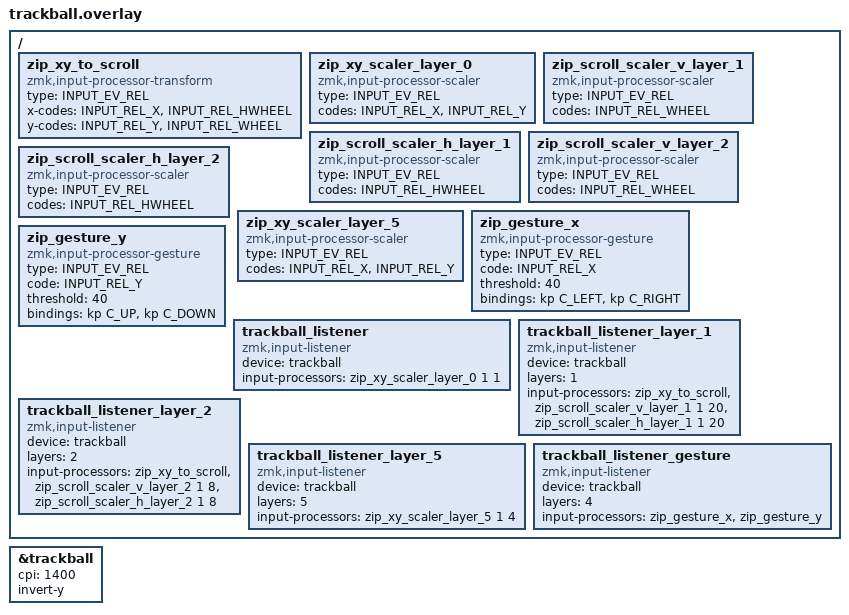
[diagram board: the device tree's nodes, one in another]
// Trackball overlay - generated by Skinner39 Studio

/ {
    // XY入力をスクロールイベントに変換する共有プロセッサ
    zip_xy_to_scroll: zip_xy_to_scroll {
        compatible = "zmk,input-processor-transform";
        #input-processor-cells = <0>;
        type = <INPUT_EV_REL>;
        x-codes = <INPUT_REL_X>, <INPUT_REL_HWHEEL>;
        y-codes = <INPUT_REL_Y>, <INPUT_REL_WHEEL>;
    };

    zip_xy_scaler_layer_0: zip_xy_scaler_layer_0 {
        compatible = "zmk,input-processor-scaler";
        #input-processor-cells = <2>;
        type = <INPUT_EV_REL>;
        codes = <INPUT_REL_X>, <INPUT_REL_Y>;
    };

    zip_scroll_scaler_v_layer_1: zip_scroll_scaler_v_layer_1 {
        compatible = "zmk,input-processor-scaler";
        #input-processor-cells = <2>;
        type = <INPUT_EV_REL>;
        codes = <INPUT_REL_WHEEL>;
    };
    zip_scroll_scaler_h_layer_1: zip_scroll_scaler_h_layer_1 {
        compatible = "zmk,input-processor-scaler";
        #input-processor-cells = <2>;
        type = <INPUT_EV_REL>;
        codes = <INPUT_REL_HWHEEL>;
    };

    zip_scroll_scaler_v_layer_2: zip_scroll_scaler_v_layer_2 {
        compatible = "zmk,input-processor-scaler";
        #input-processor-cells = <2>;
        type = <INPUT_EV_REL>;
        codes = <INPUT_REL_WHEEL>;
    };
    zip_scroll_scaler_h_layer_2: zip_scroll_scaler_h_layer_2 {
        compatible = "zmk,input-processor-scaler";
        #input-processor-cells = <2>;
        type = <INPUT_EV_REL>;
        codes = <INPUT_REL_HWHEEL>;
    };

    zip_xy_scaler_layer_5: zip_xy_scaler_layer_5 {
        compatible = "zmk,input-processor-scaler";
        #input-processor-cells = <2>;
        type = <INPUT_EV_REL>;
        codes = <INPUT_REL_X>, <INPUT_REL_Y>;
    };

    zip_gesture_x: zip_gesture_x {
        compatible = "zmk,input-processor-gesture";
        #input-processor-cells = <0>;
        type = <INPUT_EV_REL>;
        code = <INPUT_REL_X>;
        threshold = <40>;
        bindings = <&kp C_LEFT>, <&kp C_RIGHT>;
    };

    zip_gesture_y: zip_gesture_y {
        compatible = "zmk,input-processor-gesture";
        #input-processor-cells = <0>;
        type = <INPUT_EV_REL>;
        code = <INPUT_REL_Y>;
        threshold = <40>;
        bindings = <&kp C_UP>, <&kp C_DOWN>;
    };

    trackball_listener {
        compatible = "zmk,input-listener";
        device = <&trackball>;
        input-processors = <&zip_xy_scaler_layer_0 1 1>;
    };

    trackball_listener_layer_1 {
        compatible = "zmk,input-listener";
        device = <&trackball>;
        layers = <1>;
        input-processors = <&zip_xy_to_scroll>, <&zip_scroll_scaler_v_layer_1 1 20>, <&zip_scroll_scaler_h_layer_1 1 20>;
    };

    trackball_listener_layer_2 {
        compatible = "zmk,input-listener";
        device = <&trackball>;
        layers = <2>;
        input-processors = <&zip_xy_to_scroll>, <&zip_scroll_scaler_v_layer_2 1 8>, <&zip_scroll_scaler_h_layer_2 1 8>;
    };

    trackball_listener_layer_5 {
        compatible = "zmk,input-listener";
        device = <&trackball>;
        layers = <5>;
        input-processors = <&zip_xy_scaler_layer_5 1 4>;
    };

    trackball_listener_gesture {
        compatible = "zmk,input-listener";
        device = <&trackball>;
        layers = <4>;
        input-processors = <&zip_gesture_x>, <&zip_gesture_y>;
    };

};

&trackball {
    cpi = <1400>;
    invert-y;
};
